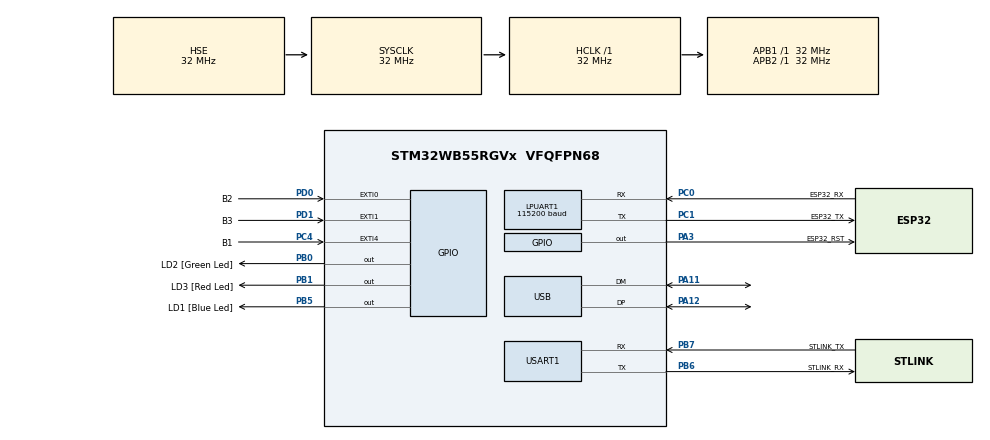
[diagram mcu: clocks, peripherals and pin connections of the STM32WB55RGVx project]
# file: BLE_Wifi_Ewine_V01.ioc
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Dma.LPUART1_RX.1.Direction=DMA_PERIPH_TO_MEMORY
Dma.LPUART1_RX.1.EventEnable=DISABLE
Dma.LPUART1_RX.1.Instance=DMA1_Channel1
Dma.LPUART1_RX.1.MemDataAlignment=DMA_MDATAALIGN_BYTE
Dma.LPUART1_RX.1.MemInc=DMA_MINC_ENABLE
Dma.LPUART1_RX.1.Mode=DMA_NORMAL
Dma.LPUART1_RX.1.PeriphDataAlignment=DMA_PDATAALIGN_BYTE
Dma.LPUART1_RX.1.PeriphInc=DMA_PINC_DISABLE
Dma.LPUART1_RX.1.Polarity=HAL_DMAMUX_REQ_GEN_RISING
Dma.LPUART1_RX.1.Priority=DMA_PRIORITY_LOW
Dma.LPUART1_RX.1.RequestNumber=1
Dma.LPUART1_RX.1.SignalID=NONE
Dma.LPUART1_RX.1.SyncEnable=DISABLE
Dma.LPUART1_RX.1.SyncPolarity=HAL_DMAMUX_SYNC_NO_EVENT
Dma.LPUART1_RX.1.SyncRequestNumber=1
Dma.LPUART1_RX.1.SyncSignalID=NONE
Dma.Request0=USART1_TX
Dma.Request1=LPUART1_RX
Dma.USART1_TX.0.Direction=DMA_MEMORY_TO_PERIPH
Dma.USART1_TX.0.EventEnable=DISABLE
Dma.USART1_TX.0.Instance=DMA2_Channel4
Dma.USART1_TX.0.MemDataAlignment=DMA_MDATAALIGN_BYTE
Dma.USART1_TX.0.MemInc=DMA_MINC_ENABLE
Dma.USART1_TX.0.Mode=DMA_NORMAL
Dma.USART1_TX.0.PeriphDataAlignment=DMA_PDATAALIGN_BYTE
Dma.USART1_TX.0.PeriphInc=DMA_PINC_DISABLE
Dma.USART1_TX.0.Polarity=HAL_DMAMUX_REQ_GEN_RISING
Dma.USART1_TX.0.Priority=DMA_PRIORITY_LOW
Dma.USART1_TX.0.RequestNumber=1
Dma.USART1_TX.0.SignalID=NONE
Dma.USART1_TX.0.SyncEnable=DISABLE
Dma.USART1_TX.0.SyncPolarity=HAL_DMAMUX_SYNC_NO_EVENT
Dma.USART1_TX.0.SyncRequestNumber=1
Dma.USART1_TX.0.SyncSignalID=NONE
LPUART1.BaudRate=115200
Mcu.Family=STM32WB
Mcu.Name=STM32WB55RGVx
Mcu.Package=VFQFPN68
NVIC.DMA1_Channel1_IRQn=true\:0\:0\:false\:false\:true\:false\:true\:true
NVIC.DMA2_Channel4_IRQn=true\:0\:0\:false\:false\:true\:false\:true\:true
NVIC.EXTI0_IRQn=true\:0\:0\:false\:false\:true\:true\:true\:true
NVIC.EXTI1_IRQn=true\:0\:0\:false\:false\:true\:true\:true\:true
NVIC.EXTI4_IRQn=true\:0\:0\:false\:false\:true\:true\:true\:true
NVIC.HSEM_IRQn=true\:0\:0\:false\:false\:true\:false\:true\:true
NVIC.IPCC_C1_RX_IRQn=true\:0\:0\:false\:false\:true\:true\:true\:true
NVIC.IPCC_C1_TX_IRQn=true\:0\:0\:false\:false\:true\:true\:true\:true
NVIC.LPUART1_IRQn=true\:0\:0\:false\:false\:true\:true\:true\:true
NVIC.PriorityGroup=NVIC_PRIORITYGROUP_4
NVIC.RTC_WKUP_IRQn=true\:0\:0\:false\:false\:true\:true\:true\:true
OSC_IN.Mode=HSE-External-Oscillator
OSC_IN.Signal=RCC_OSC_IN
OSC_OUT.Mode=HSE-External-Oscillator
OSC_OUT.Signal=RCC_OSC_OUT
PA11.Mode=Device
PA11.Signal=USB_DM
PA12.Mode=Device
PA12.Signal=USB_DP
PA13.GPIO_Label=JTMS
PA13.Mode=Serial_Wire
PA13.Signal=SYS_JTMS-SWDIO
PA14.GPIO_Label=JTCK
PA14.Mode=Serial_Wire
PA14.Signal=SYS_JTCK-SWCLK
PA3.GPIO_Label=ESP32_RST
PA3.Signal=GPIO_Output
PB0.GPIO_Label=LD2 [Green Led]
PB0.Signal=GPIO_Output
PB1.GPIO_Label=LD3 [Red Led]
PB1.Signal=GPIO_Output
PB5.GPIO_Label=LD1 [Blue Led]
PB5.Signal=GPIO_Output
PB6.GPIO_Label=STLINK_RX
PB6.GPIO_PuPd=GPIO_PULLUP
PB6.Mode=Asynchronous
PB6.Signal=USART1_TX
PB7.GPIO_Label=STLINK_TX
PB7.GPIO_PuPd=GPIO_PULLUP
PB7.Mode=Asynchronous
PB7.Signal=USART1_RX
PC0.GPIO_Label=ESP32_RX
PC0.Mode=Asynchronous
PC0.Signal=LPUART1_RX
PC1.GPIO_Label=ESP32_TX
PC1.Mode=Asynchronous
PC1.Signal=LPUART1_TX
PC13.Mode=SYS_WakeUp1
PC13.Signal=SYS_WKUP2
PC14-OSC32_IN.Mode=LSE-External-Oscillator
PC14-OSC32_IN.Signal=RCC_OSC32_IN
PC15-OSC32_OUT.Mode=LSE-External-Oscillator
PC15-OSC32_OUT.Signal=RCC_OSC32_OUT
PC4.GPIO_Label=B1
PC4.GPIO_PuPd=GPIO_PULLUP
PC4.Signal=GPXTI4
PD0.GPIO_Label=B2
PD0.GPIO_PuPd=GPIO_PULLUP
PD0.Signal=GPXTI0
PD1.GPIO_Label=B3
PD1.GPIO_PuPd=GPIO_PULLUP
PD1.Signal=GPXTI1
ProjectManager.HeapSize=0x200
ProjectManager.StackSize=0x400
ProjectManager.TargetToolchain=STM32CubeIDE
RCC.ADCFreq_Value=48000000
RCC.AHBFreq_Value=32000000
RCC.APB1Freq_Value=32000000
RCC.APB1TimFreq_Value=32000000
RCC.APB2Freq_Value=32000000
RCC.APB2TimFreq_Value=32000000
RCC.APB3Freq_Value=16000000
RCC.CortexFreq_Value=32000000
RCC.HCLKFreq_Value=32000000
RCC.HSE_VALUE=32000000
RCC.HSI48_VALUE=48000000
RCC.HSI_VALUE=16000000
RCC.PLLN=32
RCC.PLLSAI1N=24
RCC.SMPSCLockSelectionVirtual=RCC_SMPSCLKSOURCE_HSI
RCC.SMPSCLockSelectionVirtualVirtual=RCC_SMPSCLKSOURCE_HSI
RCC.SMPSDivider=1
RCC.SYSCLKFreq_VALUE=32000000
RCC.SYSCLKSource=RCC_SYSCLKSOURCE_HSE
RCC.USBFreq_Value=48000000
RCC.VCOOutputFreq_Value=128000000
RF1.Mode=RF1_Activate
RF1.Signal=RF_RF1
STM32_WPAN.AD_SERVICE_CLASS_UUID_1=FE ED
STM32_WPAN.AD_SERVICE_CLASS_UUID_1_INV=[ED, FE]
STM32_WPAN.AD_SERVICE_CLASS_UUID_2=BE EF
STM32_WPAN.AD_SERVICE_CLASS_UUID_2_INV=[EF, BE]
STM32_WPAN.AD_SERVICE_CLASS_UUID_NBR=2
STM32_WPAN.AD_TYPE_COMPLETE_LOCAL_NAME=Ewine
STM32_WPAN.AD_TYPE_COMPLETE_LOCAL_NAME_LENGTH=6
STM32_WPAN.CFG_DEBUG_APP_TRACE=1
STM32_WPAN.CFG_DEBUG_BLE_TRACE=1
STM32_WPAN.CFG_DEBUG_TRACE_FULL=1
STM32_WPAN.CFG_DEBUG_TRACE_UART=hw_uart1
STM32_WPAN.CFG_GAP_DEVICE_NAME=TPBLE
STM32_WPAN.CFG_GAP_DEVICE_NAME_LENGTH=5
STM32_WPAN.CFG_HW_USART1_ENABLED=1
STM32_WPAN.CUSTOM_P2P_SERVER=Disabled
STM32_WPAN.CUSTOM_TEMPLATE=Enabled
STM32_WPAN.GAP_PERIPHERAL_ROLE=1
STM32_WPAN.INCLUDE_AD_TYPE_16_BIT_SERV_UUID_CMPLT_LIST=1
STM32_WPAN.INCLUDE_AD_TYPE_COMPLETE_LOCAL_NAME=1
STM32_WPAN.INCLUDE_AD_TYPE_MANUFACTURER_SPECIFIC_DATA=1
STM32_WPAN.INCLUDE_AD_TYPE_TX_POWER_LEVEL=1
STM32_WPAN.NUMBER_OF_SERVICES=1
STM32_WPAN.SERVICE1_CHAR1_GATT_NOTIFY_READ_REQ_AND_WAIT_FOR_APPL_RESP=\ 
STM32_WPAN.SERVICE1_CHAR1_GATT_NOTIFY_WRITE_REQ_AND_WAIT_FOR_APPL_RESP=\ 
STM32_WPAN.SERVICE1_CHAR1_LENGTH_CHARACTERISTIC=CHAR_VALUE_LEN_VARIABLE
STM32_WPAN.SERVICE1_CHAR1_LONG_NAME=get_ssid
STM32_WPAN.SERVICE1_CHAR1_PROP_READ=CHAR_PROP_READ
STM32_WPAN.SERVICE1_CHAR1_PROP_WRITE_WITHOUT_RESP=CHAR_PROP_WRITE_WITHOUT_RESP
STM32_WPAN.SERVICE1_CHAR1_SHORT_NAME=gssid
STM32_WPAN.SERVICE1_CHAR1_UUID=AB CD
STM32_WPAN.SERVICE1_CHAR1_VALUE_LENGTH=30
STM32_WPAN.SERVICE1_CHAR2_GATT_NOTIFY_READ_REQ_AND_WAIT_FOR_APPL_RESP=\ 
STM32_WPAN.SERVICE1_CHAR2_GATT_NOTIFY_WRITE_REQ_AND_WAIT_FOR_APPL_RESP=\ 
STM32_WPAN.SERVICE1_CHAR2_LENGTH_CHARACTERISTIC=CHAR_VALUE_LEN_VARIABLE
STM32_WPAN.SERVICE1_CHAR2_LONG_NAME=get_password
STM32_WPAN.SERVICE1_CHAR2_PROP_READ=CHAR_PROP_READ
STM32_WPAN.SERVICE1_CHAR2_PROP_WRITE_WITHOUT_RESP=CHAR_PROP_WRITE_WITHOUT_RESP
STM32_WPAN.SERVICE1_CHAR2_SHORT_NAME=gpass
STM32_WPAN.SERVICE1_CHAR2_UUID=12 34
STM32_WPAN.SERVICE1_CHAR2_VALUE_LENGTH=30
STM32_WPAN.SERVICE1_CHAR3_GATT_NOTIFY_READ_REQ_AND_WAIT_FOR_APPL_RESP=\ 
STM32_WPAN.SERVICE1_CHAR3_GATT_NOTIFY_WRITE_REQ_AND_WAIT_FOR_APPL_RESP=\ 
STM32_WPAN.SERVICE1_CHAR3_LONG_NAME=status_connection
STM32_WPAN.SERVICE1_CHAR3_PROP_NOTIFY=CHAR_PROP_NOTIFY
STM32_WPAN.SERVICE1_CHAR3_SHORT_NAME=ack
STM32_WPAN.SERVICE1_CHAR3_UUID=DE AD
STM32_WPAN.SERVICE1_LONG_NAME=First_service
STM32_WPAN.SERVICE1_NUMBER_OF_CHARACTERISTICS=3
STM32_WPAN.SERVICE1_SHORT_NAME=fs
STM32_WPAN.SERVICE1_UUID=FE ED
STM32_WPAN.SERVICE2_CHAR1_GATT_NOTIFY_READ_REQ_AND_WAIT_FOR_APPL_RESP=\ 
STM32_WPAN.SERVICE2_CHAR1_GATT_NOTIFY_WRITE_REQ_AND_WAIT_FOR_APPL_RESP=\ 
STM32_WPAN.SERVICE2_CHAR1_LONG_NAME=echo_char
STM32_WPAN.SERVICE2_CHAR1_PROP_NOTIFY=CHAR_PROP_NOTIFY
STM32_WPAN.SERVICE2_CHAR1_SHORT_NAME=ec
STM32_WPAN.SERVICE2_CHAR1_UUID=CD EF
STM32_WPAN.SERVICE2_LONG_NAME=echo_service
STM32_WPAN.SERVICE2_SHORT_NAME=es
STM32_WPAN.SERVICE2_UUID=BE EF
USART1.VirtualMode-Asynchronous=VM_ASYNC
USART1.WordLength=WORDLENGTH_8B
VP_HSEM_VS_HSEM.Mode=HSEM_Activate
VP_IPCC_VS_IPCC.Mode=IPCC_Activate
VP_RTC_VS_RTC_Activate.Mode=RTC_Enabled
VP_RTC_VS_RTC_WakeUp_intern.Mode=WakeUp
VP_SEQUENCER_VS_SEQUENCER.Mode=SEQUENCER_Enabled
VP_STM32_WPAN_VS_BLE_HOST.Mode=STM32_WPAN_Enabled
VP_TINY_LPM_VS_TINY_LPM.Mode=TINY_LPM_Enabled
board=NUCLEO-WB55RG

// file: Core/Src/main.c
/* USER CODE BEGIN Header */
/**
  ******************************************************************************
  * @file           : main.c
  * @brief          : Main program body
  ******************************************************************************
  * @attention
  *
  * Copyright (c) 2023 STMicroelectronics.
  * All rights reserved.
  *
  * This software is licensed under terms that can be found in the LICENSE file
  * in the root directory of this software component.
  * If no LICENSE file comes with this software, it is provided AS-IS.
  *
  ******************************************************************************
  */
/* USER CODE END Header */
#include "main.h"
#include "dma.h"
#include "ipcc.h"
#include "usart.h"
#include "rf.h"
#include "rtc.h"
#include "usb.h"
#include "gpio.h"

/* USER CODE BEGIN Includes */
#include "app_wifi.h"
/* USER CODE END Includes */

void SystemClock_Config(void);
void PeriphCommonClock_Config(void);
/* USER CODE BEGIN PFP */
uint32_t GetPage(uint32_t Address);
int _write(int file, char *ptr, int len);
/* USER CODE END PFP */

/* USER CODE BEGIN 0 */
int _write(int file, char *ptr, int len)
{
	int DataIdx;
	for (DataIdx = 0; DataIdx < len; DataIdx++)
	{
		//__io_putchar(*ptr++);
		ITM_SendChar(*ptr++);
	}
	return len;
}
/* USER CODE END 0 */

int main(void)
{

  /* MCU Configuration--------------------------------------------------------*/

  /* Reset of all peripherals, Initializes the Flash interface and the Systick. */
  HAL_Init();
  /* Config code for STM32_WPAN (HSE Tuning must be done before system clock configuration) */
  MX_APPE_Config();

  /* Configure the system clock */
  SystemClock_Config();

/* Configure the peripherals common clocks */
  PeriphCommonClock_Config();

  /* IPCC initialisation */
  MX_IPCC_Init();

  /* Initialize all configured peripherals */
  MX_GPIO_Init();
  MX_DMA_Init();
  MX_RTC_Init();
  MX_USART1_UART_Init();
  MX_USB_PCD_Init();
  MX_LPUART1_UART_Init();
  MX_RF_Init();
  /* USER CODE BEGIN 2 */
  HAL_GPIO_WritePin(GPIOB, GPIO_PIN_1, RESET);
  HAL_GPIO_WritePin(GPIOB, GPIO_PIN_0, RESET);
  HAL_GPIO_WritePin(GPIOB, GPIO_PIN_5, RESET);
  /* USER CODE END 2 */

  /* Init code for STM32_WPAN */
  MX_APPE_Init();

  /* Infinite loop */
  while (1)
  {
    MX_APPE_Process();

  }
}

void SystemClock_Config(void)
{
  RCC_OscInitTypeDef RCC_OscInitStruct = {0};
  RCC_ClkInitTypeDef RCC_ClkInitStruct = {0};

  /** Macro to configure the PLL multiplication factor
  */
  __HAL_RCC_PLL_PLLM_CONFIG(RCC_PLLM_DIV1);

  /** Macro to configure the PLL clock source
  */
  __HAL_RCC_PLL_PLLSOURCE_CONFIG(RCC_PLLSOURCE_MSI);

  /** Configure LSE Drive Capability
  */
  HAL_PWR_EnableBkUpAccess();
  __HAL_RCC_LSEDRIVE_CONFIG(RCC_LSEDRIVE_MEDIUMHIGH);

  /** Configure the main internal regulator output voltage
  */
  __HAL_PWR_VOLTAGESCALING_CONFIG(PWR_REGULATOR_VOLTAGE_SCALE1);

  /** Initializes the RCC Oscillators according to the specified parameters
  * in the RCC_OscInitTypeDef structure.
  */
  RCC_OscInitStruct.OscillatorType = RCC_OSCILLATORTYPE_HSI|RCC_OSCILLATORTYPE_LSI1
                              |RCC_OSCILLATORTYPE_HSE|RCC_OSCILLATORTYPE_LSE
                              |RCC_OSCILLATORTYPE_MSI;
  RCC_OscInitStruct.HSEState = RCC_HSE_ON;
  RCC_OscInitStruct.LSEState = RCC_LSE_ON;
  RCC_OscInitStruct.HSIState = RCC_HSI_ON;
  RCC_OscInitStruct.MSIState = RCC_MSI_ON;
  RCC_OscInitStruct.HSICalibrationValue = RCC_HSICALIBRATION_DEFAULT;
  RCC_OscInitStruct.MSICalibrationValue = RCC_MSICALIBRATION_DEFAULT;
  RCC_OscInitStruct.MSIClockRange = RCC_MSIRANGE_6;
  RCC_OscInitStruct.LSIState = RCC_LSI_ON;
  RCC_OscInitStruct.PLL.PLLState = RCC_PLL_NONE;
  if (HAL_RCC_OscConfig(&RCC_OscInitStruct) != HAL_OK)
  {
    Error_Handler();
  }

  /** Configure the SYSCLKSource, HCLK, PCLK1 and PCLK2 clocks dividers
  */
  RCC_ClkInitStruct.ClockType = RCC_CLOCKTYPE_HCLK4|RCC_CLOCKTYPE_HCLK2
                              |RCC_CLOCKTYPE_HCLK|RCC_CLOCKTYPE_SYSCLK
                              |RCC_CLOCKTYPE_PCLK1|RCC_CLOCKTYPE_PCLK2;
  RCC_ClkInitStruct.SYSCLKSource = RCC_SYSCLKSOURCE_HSE;
  RCC_ClkInitStruct.AHBCLKDivider = RCC_SYSCLK_DIV1;
  RCC_ClkInitStruct.APB1CLKDivider = RCC_HCLK_DIV1;
  RCC_ClkInitStruct.APB2CLKDivider = RCC_HCLK_DIV1;
  RCC_ClkInitStruct.AHBCLK2Divider = RCC_SYSCLK_DIV1;
  RCC_ClkInitStruct.AHBCLK4Divider = RCC_SYSCLK_DIV1;

  if (HAL_RCC_ClockConfig(&RCC_ClkInitStruct, FLASH_LATENCY_1) != HAL_OK)
  {
    Error_Handler();
  }

  /** Enable MSI Auto calibration
  */
  HAL_RCCEx_EnableMSIPLLMode();
}

void PeriphCommonClock_Config(void)
{
  RCC_PeriphCLKInitTypeDef PeriphClkInitStruct = {0};

  /** Initializes the peripherals clock
  */
  PeriphClkInitStruct.PeriphClockSelection = RCC_PERIPHCLK_SMPS|RCC_PERIPHCLK_RFWAKEUP;
  PeriphClkInitStruct.RFWakeUpClockSelection = RCC_RFWKPCLKSOURCE_HSE_DIV1024;
  PeriphClkInitStruct.SmpsClockSelection = RCC_SMPSCLKSOURCE_HSI;
  PeriphClkInitStruct.SmpsDivSelection = RCC_SMPSCLKDIV_RANGE0;

  if (HAL_RCCEx_PeriphCLKConfig(&PeriphClkInitStruct) != HAL_OK)
  {
    Error_Handler();
  }
}

/* USER CODE BEGIN 4 */
uint32_t GetPage(uint32_t Addr)
{
  return (Addr - FLASH_BASE) / FLASH_PAGE_SIZE;;
}
/* USER CODE END 4 */

void Error_Handler(void)
{
  __disable_irq();
  while (1)
  {
  }
}
